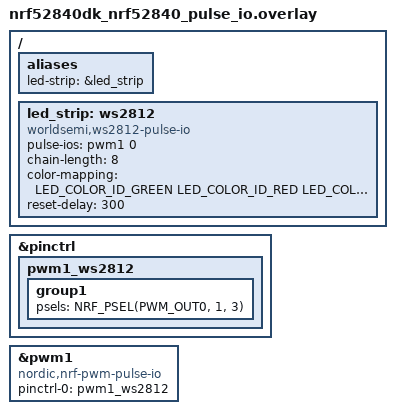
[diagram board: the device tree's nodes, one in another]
/*
 * SPDX-FileCopyrightText: Copyright The Zephyr Project Contributors
 * Copyright (c) 2026 Dev It Wise
 *
 * SPDX-License-Identifier: Apache-2.0
 */

#include <zephyr/dt-bindings/led/led.h>

/ {
	aliases {
		led-strip = &led_strip;
	};

	led_strip: ws2812 {
		compatible = "worldsemi,ws2812-pulse-io";
		pulse-ios = <&pwm1 0>;
		chain-length = <8>;
		color-mapping = <LED_COLOR_ID_GREEN
				 LED_COLOR_ID_RED
				 LED_COLOR_ID_BLUE>;
		reset-delay = <300>;
	};
};

&pinctrl {
	pwm1_ws2812: pwm1_ws2812 {
		group1 {
			psels = <NRF_PSEL(PWM_OUT0, 1, 3)>;
		};
	};
};

&pwm1 {
	compatible = "nordic,nrf-pwm-pulse-io";
	status = "okay";
	#pulse-io-cells = <1>;
	pinctrl-0 = <&pwm1_ws2812>;
	pinctrl-names = "default";
};
